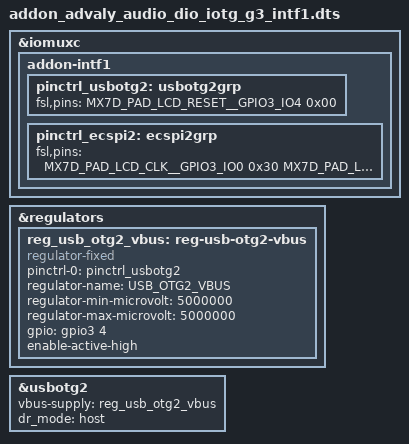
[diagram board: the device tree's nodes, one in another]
// SPDX-License-Identifier: GPL-2.0
/*
 * Copyright (C) 2024 ADVALY SYSTEM Inc. All Rights Reserved.
 */

#include "../../../../arch/arm/boot/dts/imx7d-pinfunc.h"

/dts-v1/;
/plugin/;
/ {
	fragment@0 {
		target = <&iomuxc>;
		__overlay__ {
			addon-intf1 {
				pinctrl_usbotg2: usbotg2grp {
					fsl,pins = <
						MX7D_PAD_LCD_RESET__GPIO3_IO4 0x00	/* GPIO_AOM1_VBUS_PWREN */
					>;
				};

				pinctrl_ecspi2: ecspi2grp {
					fsl,pins = <
						MX7D_PAD_LCD_CLK__GPIO3_IO0		0x30	/* INTF1_3 */
						MX7D_PAD_LCD_ENABLE__GPIO3_IO1		0x30	/* INTF1_4 */

						MX7D_PAD_ENET1_TX_CLK__GPIO7_IO12	0x30	/* INTF1_32 */
						MX7D_PAD_ENET1_RX_CLK__GPIO7_IO13	0x30	/* INTF1_33 */

						MX7D_PAD_ENET1_RGMII_RD0__GPIO7_IO0	0x30	/* INTF1_38 */
						MX7D_PAD_ENET1_RGMII_RD1__GPIO7_IO1	0x30	/* INTF1_39 */
						MX7D_PAD_ENET1_RGMII_RD2__GPIO7_IO2	0x30	/* INTF1_35 */
						MX7D_PAD_ENET1_RGMII_RD3__GPIO7_IO3	0x30	/* INTF1_37 */

						MX7D_PAD_ENET1_RGMII_RX_CTL__GPIO7_IO4	0x30	/* INTF1_42 */
						MX7D_PAD_ENET1_RGMII_RXC__GPIO7_IO5	0x30	/* INTF1_43 */
						MX7D_PAD_ENET1_RGMII_TD0__GPIO7_IO6	0x30	/* INTF1_44 */
						MX7D_PAD_ENET1_RGMII_TX_CTL__GPIO7_IO10	0x30	/* INTF1_45 */
						MX7D_PAD_ENET1_RGMII_TXC__GPIO7_IO11	0x30	/* INTF1_46 */
						MX7D_PAD_SD2_CLK__GPIO5_IO12		0x30	/* INTF1_47 */
						MX7D_PAD_SD2_CMD__GPIO5_IO13		0x30	/* INTF1_48 */
						MX7D_PAD_SD2_DATA0__GPIO5_IO14		0x30	/* INTF1_49 */
						MX7D_PAD_UART1_RX_DATA__GPIO4_IO0	0x30	/* INTF1_41 */
					>;
				};
			};
		};
	};

	fragment@1 {
		target = <&regulators>;
		__overlay__ {
			reg_usb_otg2_vbus: reg-usb-otg2-vbus {
				compatible = "regulator-fixed";
				pinctrl-names = "default";
				pinctrl-0 = <&pinctrl_usbotg2>;
				regulator-name = "USB_OTG2_VBUS";
				regulator-min-microvolt = <5000000>;
				regulator-max-microvolt = <5000000>;
				gpio = <&gpio3 4 0>;
				enable-active-high;
			};
		};
	};

	fragment@2 {
		target = <&usbotg2>;
		__overlay__ {
			vbus-supply = <&reg_usb_otg2_vbus>;
			dr_mode = "host";
			status = "okay";
		};
	};

};
